# f28p65x_sync_soc_regs register map
Vendor: Texas Instruments
Peripheral module from a debugger description file (folder C2000).
Address unit: 16 bits
Registers are 32-bit, read-write, no defined reset value unless marked. A register's access mark holds for its fields unless they carry their own. Offsets are as the file gives them; lines under a group give offsets from that group; [hi:lo] are bit positions; {n}, {i} and the like mark numbered series; 'fields as' and 'values as' point back to an identical list; <NAME> marks a mode.

## SYNC_SOC_REGS — SYNC SOC Registers
0x00 SYNCSELECT — Sync Input and Output Select Register
  [28:24] SYNCOUT — Select Syncout Source
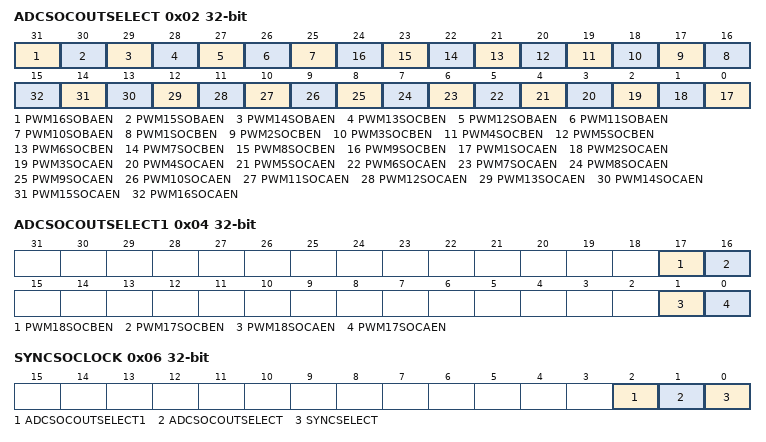
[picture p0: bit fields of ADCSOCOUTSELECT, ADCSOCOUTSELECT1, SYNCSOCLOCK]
0x02 ADCSOCOUTSELECT — External ADCSOC Select Register (PWM1-16)
  [31] PWM16SOBAEN — PWM16SOBAEN Enable for ADCSOCBOn
  [30] PWM15SOBAEN — PWM15SOBAEN Enable for ADCSOCBOn
  [29] PWM14SOBAEN — PWM14SOBAEN Enable for ADCSOCBOn
  [28] PWM13SOCBEN — PWM13SOCBEN Enable for ADCSOCBOn
  [27] PWM12SOBAEN — PWM12SOBAEN Enable for ADCSOCBOn
  [26] PWM11SOBAEN — PWM11SOBAEN Enable for ADCSOCBOn
  [25] PWM10SOBAEN — PWM10SOBAEN Enable for ADCSOCBOn
  [n+15] PWM{n}SOCBEN (n=1..9) — PWM{n}SOCBEN Enable for ADCSOCBOn
  [n-1] PWM{n}SOCAEN (n=1..16) — PWM{n}SOCAEN Enable for ADCSOCAOn
0x04 ADCSOCOUTSELECT1 — External ADCSOC Select Register (PWM17-32)
  [17] PWM18SOCBEN — PWM18SOCBEN Enable for ADCSOCBOn
  [16] PWM17SOCBEN — PWM17SOCBEN Enable for ADCSOCBOn
  [1] PWM18SOCAEN — PWM18SOCAEN Enable for ADCSOCAOn
  [0] PWM17SOCAEN — PWM17SOCAEN Enable for ADCSOCAOn
0x06 SYNCSOCLOCK — SYNCSEL and EXTADCSOC Select Lock register
  [2] ADCSOCOUTSELECT1 — ADCSOCOUTSELECT1 Register Lock bit
  [1] ADCSOCOUTSELECT — ADCSOCOUTSELECT Register Lock bit
  [0] SYNCSELECT — SYNCSEL Register Lock bit
